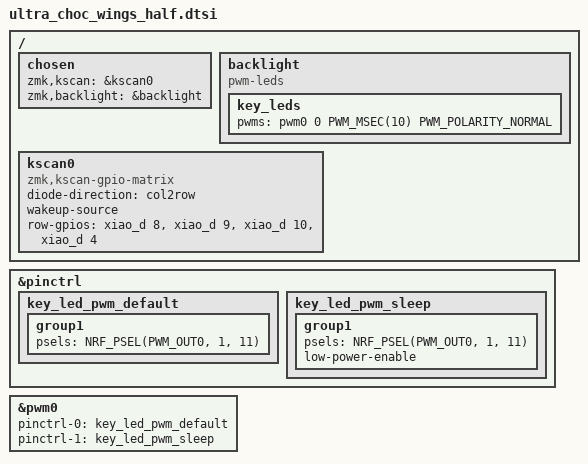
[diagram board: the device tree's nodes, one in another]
/*
 * Common to both halves: key matrix and the per-key LED backlight.
 *
 * All 18 LEDs share one low-side MOSFET whose gate is on D6 (P1.11), so the
 * backlight is a single PWM channel. It is off at boot, starts at 10 % and
 * switches off when the half goes idle (see ultra_choc_wings_half.conf).
 */

#include "ultra_choc_wings.dtsi"
#include <dt-bindings/led/led.h>

&pinctrl {
    key_led_pwm_default: key_led_pwm_default {
        group1 {
            psels = <NRF_PSEL(PWM_OUT0, 1, 11)>;
        };
    };

    key_led_pwm_sleep: key_led_pwm_sleep {
        group1 {
            psels = <NRF_PSEL(PWM_OUT0, 1, 11)>;
            low-power-enable;
        };
    };
};

&pwm0 {
    status = "okay";
    pinctrl-0 = <&key_led_pwm_default>;
    pinctrl-1 = <&key_led_pwm_sleep>;
    pinctrl-names = "default", "sleep";
};

/ {
    chosen {
        zmk,kscan = &kscan0;
        zmk,backlight = &backlight;
    };

    backlight: backlight {
        compatible = "pwm-leds";
        key_leds: key_leds {
            pwms = <&pwm0 0 PWM_MSEC(10) PWM_POLARITY_NORMAL>;
        };
    };

    kscan0: kscan0 {
        compatible = "zmk,kscan-gpio-matrix";
        diode-direction = "col2row";
        wakeup-source;

        row-gpios
            = <&xiao_d 8 (GPIO_ACTIVE_HIGH | GPIO_PULL_DOWN)>
            , <&xiao_d 9 (GPIO_ACTIVE_HIGH | GPIO_PULL_DOWN)>
            , <&xiao_d 10 (GPIO_ACTIVE_HIGH | GPIO_PULL_DOWN)>
            , <&xiao_d 4 (GPIO_ACTIVE_HIGH | GPIO_PULL_DOWN)>
            ;
    };
};
